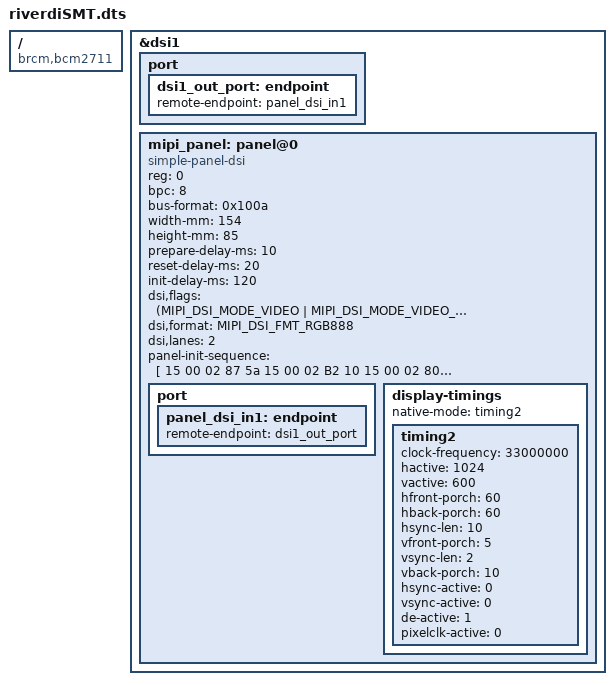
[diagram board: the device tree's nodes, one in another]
/dts-v1/;
/plugin/;

#include "../include/mipi_dsi.h"

/ {
	//Changed from BCM2835
	compatible = "brcm,bcm2711";

	fragment@0 {
		target = <&dsi1>;

		__overlay__  {
			status = "okay";

			#address-cells = <1>;
			#size-cells = <0>;

			port {
				dsi1_out_port: endpoint {
					remote-endpoint = <&panel_dsi_in1>;
				};
			};

			//mipi_panel: mipi_panel
			mipi_panel: panel@0 {
				compatible = "simple-panel-dsi";
				reg = <0>;
			
				//enable-gpios = <&gpio6 3 GPIO_ACTIVE_LOW>;
				//reset-gpios = <&gpio6 4 GPIO_ACTIVE_HIGH>;
			
				bpc = <8>;
				bus-format = <0x100a>;
			
				width-mm = <154>;
				height-mm = <85>;
			
				prepare-delay-ms = <10>;
				reset-delay-ms = <20>;
				init-delay-ms = <120>;
			
				dsi,flags = <(MIPI_DSI_MODE_VIDEO | MIPI_DSI_MODE_VIDEO_BURST | MIPI_DSI_MODE_LPM)>;
				dsi,format = <MIPI_DSI_FMT_RGB888>;
				dsi,lanes = <2>;
			
				panel-init-sequence = [
					15 00 02 87 5a
					15 00 02 B2 10
					15 00 02 80 4B
					15 00 02 81 FF
					15 00 02 82 1A
					15 00 02 83 88
					15 00 02 84 8F
					15 00 02 85 35
					15 00 02 86 B0
					05 00 01 21
				];

				port {
					panel_dsi_in1: endpoint {
						remote-endpoint = <&dsi1_out_port>;
					};
				};
	
				display-timings {
					native-mode = <&timing2>;
					//timing2: timing2
					timing2: timing2 {
						clock-frequency = <33000000>; //dclk
						hactive = <1024>; //hactive
						vactive = <600>; //vactive
						hfront-porch = <60>; //hfp
						hback-porch = <60>; //hbp
						hsync-len = <10>; //hsa
						vfront-porch = <5>; //vfp
						vsync-len = <2>; //vsa
						vback-porch = <10>; //vbp
						hsync-active = <0>; //hync active control
						vsync-active = <0>; //vsync active control
						de-active = <1>; //den active control
						pixelclk-active = <0>; //dclk active control
					};
				};
			};
		
		};
	};
};
